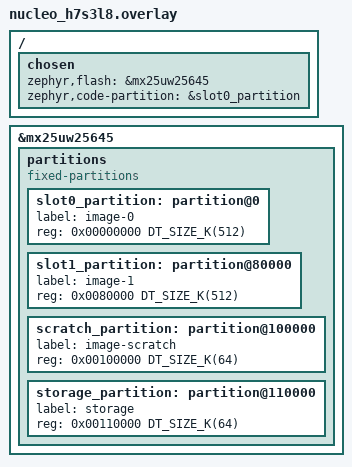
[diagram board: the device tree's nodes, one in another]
/*
 * Copyright (c) 2025 STMicroelectronics
 *
 * SPDX-License-Identifier: Apache-2.0
 */

/*
 * Define the device, controller and partition to be the external memory
 * for running the application in external NOR from MCUboot
 */
/ {
	chosen {
		zephyr,flash = &mx25uw25645;
		zephyr,code-partition = &slot0_partition;
	};
};

&mx25uw25645 {
		partitions {
			compatible = "fixed-partitions";
			#address-cells = <1>;
			#size-cells = <1>;

			slot0_partition: partition@0 {
				label = "image-0";
				reg = <0x00000000 DT_SIZE_K(512)>;
			};
			slot1_partition: partition@80000 {
				label = "image-1";
				reg = <0x0080000 DT_SIZE_K(512)>;
			};
			scratch_partition: partition@100000 {
				label = "image-scratch";
				reg = <0x00100000 DT_SIZE_K(64)>;
			};
			storage_partition: partition@110000 {
				label = "storage";
				reg = <0x00110000 DT_SIZE_K(64)>;
			};
		};
};
